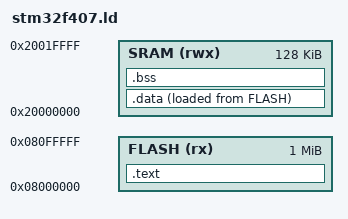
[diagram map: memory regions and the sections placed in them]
ENTRY(Reset_Handler)

MEMORY
{
    FLASH (rx)  : ORIGIN = 0x08000000, LENGTH = 1024K
    SRAM  (rwx) : ORIGIN = 0x20000000, LENGTH = 128K
}

_estack = ORIGIN(SRAM) + LENGTH(SRAM);   /* 0x20020000 — top of 128KB SRAM */

SECTIONS
{
    .text :
    {
        KEEP(*(.isr_vector))
        *(.text*)
        *(.rodata*)
        . = ALIGN(4);
    } > FLASH

    .data :
    {
        _sdata = .;
        *(.data*)
        . = ALIGN(4);
        _edata = .;
    } > SRAM AT > FLASH
    _la_data = LOADADDR(.data);

    .bss :
    {
        _sbss = .;
        *(.bss*)
        *(COMMON)
        . = ALIGN(4);
        _ebss = .;
    } > SRAM
}
